# STM32WBA52 register map
File version: 0.1
CPU: CM33 r0p1, little endian, MPU, FPU, 4 interrupt priority bits
Registers are 32-bit, read-write, reset 0x0 unless marked. A register's access mark holds for its fields unless they carry their own. Offsets are from the block's base; [hi:lo] are bit positions; lines under a group give offsets from that group; {n}, {i} and the like mark numbered series; 'fields as' and 'values as' point back to an identical list.

## TSC — Touch sensing controller
Base 0x40024000
Same registers: SEC_TSC 0x50024000
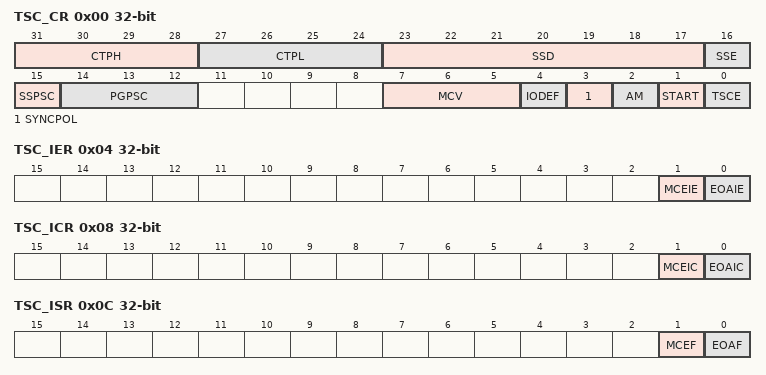
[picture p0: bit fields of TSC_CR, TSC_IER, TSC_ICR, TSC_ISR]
0x00 TSC_CR — TSC control register
  [31:28] CTPH — Charge transfer pulse high These bits are set and cleared by software. They define the duration of the high state of the charge transfer pulse (charge of C<sub>X</sub>). ... Note: These bits must not be modified when an acquisition is ongoing.
    0=1x t<sub>PGCLK</sub>; 1=2x t<sub>PGCLK</sub>; 15=16x t<sub>PGCLK</sub>
  [27:24] CTPL — Charge transfer pulse low These bits are set and cleared by software. They define the duration of the low state of the charge transfer pulse (transfer of charge from C<sub>X</sub> to C<sub>S</sub>). ... Note: These bits must not be modified when an acquisition is ongoing. Note: Some configurations are forbidden. Refer to the Section�21.3.4: Charge transfer acquisition sequence for details.
    values as CTPH
  [23:17] SSD — Spread spectrum deviation These bits are set and cleared by software. They define the spread spectrum deviation which consists in adding a variable number of periods of the SSCLK clock to the charge transfer pulse high state. ... Note: These bits must not be modified when an acquisition is ongoing.
    0=1x t<sub>SSCLK</sub>; 1=2x t<sub>SSCLK</sub>; 127=128x t<sub>SSCLK</sub>
  [16] SSE — Spread spectrum enable This bit is set and cleared by software to enable/disable the spread spectrum feature. Note: This bit must not be modified when an acquisition is ongoing.
    0=Spread spectrum disabled; 1=Spread spectrum enabled
  [15] SSPSC — Spread spectrum prescaler This bit is set and cleared by software. It selects the AHB clock divider used to generate the spread spectrum clock (SSCLK). Note: This bit must not be modified when an acquisition is ongoing.
    0=f<sub>HCLK</sub>; 1=f<sub>HCLK</sub> /2
  [14:12] PGPSC — Pulse generator prescaler These bits are set and cleared by software.They select the AHB clock divider used to generate the pulse generator clock (PGCLK). Note: These bits must not be modified when an acquisition is ongoing. Note: Some configurations are forbidden. Refer to the Section�21.3.4: Charge transfer acquisition sequence for details.
    0=f<sub>HCLK</sub>; 1=f<sub>HCLK</sub> /2; 2=f<sub>HCLK</sub> /4; 3=f<sub>HCLK</sub> /8; 4=f<sub>HCLK</sub> /16; 5=f<sub>HCLK</sub> /32; 6=f<sub>HCLK</sub> /64; 7=f<sub>HCLK</sub> /128
  [7:5] MCV — Max count value These bits are set and cleared by software. They define the maximum number of charge transfer pulses that can be generated before a max count error is generated. Note: These bits must not be modified when an acquisition is ongoing.
    0=255; 1=511; 2=1023; 3=2047; 4=4095; 5=8191; 6=16383
  [4] IODEF — I/O Default mode This bit is set and cleared by software. It defines the configuration of all the TSC I/Os when there is no ongoing acquisition. When there is an ongoing acquisition, it defines the configuration of all unused I/Os (not defined as sampling capacitor I/O or as channel I/O). Note: This bit must not be modified when an acquisition is ongoing.
    0=I/Os are forced to output push-pull low; 1=I/Os are in input floating
  [3] SYNCPOL — Synchronization pin polarity This bit is set and cleared by software to select the polarity of the synchronization input pin.
    0=Falling edge only; 1=Rising edge and high level
  [2] AM — Acquisition mode This bit is set and cleared by software to select the acquisition mode. Note: This bit must not be modified when an acquisition is ongoing.
    0=Normal acquisition mode (acquisition starts as soon as START bit is set); 1=Synchronized acquisition mode (acquisition starts if START bit is set and when the selected signal is detected on the SYNC input pin)
  [1] START — Start a new acquisition This bit is set by software to start a new acquisition. It is cleared by hardware as soon as the acquisition is complete or by software to cancel the ongoing acquisition.
    0=Acquisition not started; 1=Start a new acquisition
  [0] TSCE — Touch sensing controller enable This bit is set and cleared by software to enable/disable the touch sensing controller. Note: When the touch sensing controller is disabled, TSC registers settings have no effect.
    0=Touch sensing controller disabled; 1=Touch sensing controller enabled
0x04 TSC_IER — TSC interrupt enable register
  [1] MCEIE — Max count error interrupt enable This bit is set and cleared by software to enable/disable the max count error interrupt.
    0=Max count error interrupt disabled; 1=Max count error interrupt enabled
  [0] EOAIE — End of acquisition interrupt enable This bit is set and cleared by software to enable/disable the end of acquisition interrupt.
    0=End of acquisition interrupt disabled; 1=End of acquisition interrupt enabled
0x08 TSC_ICR — TSC interrupt clear register
  [1] MCEIC — Max count error interrupt clear This bit is set by software to clear the max count error flag and it is cleared by hardware when the flag is reset. Writing a ‘0’ has no effect.
    0=No effect; 1=Clears the corresponding MCEF of the TSC_ISR register
  [0] EOAIC — End of acquisition interrupt clear This bit is set by software to clear the end of acquisition flag and it is cleared by hardware when the flag is reset. Writing a ‘0’ has no effect.
    0=No effect; 1=Clears the corresponding EOAF of the TSC_ISR register
0x0C TSC_ISR ro — TSC interrupt status register
  [1] MCEF — Max count error flag This bit is set by hardware as soon as an analog I/O group counter reaches the max count value specified. It is cleared by software writing 1 to the bit MCEIC of the TSC_ICR register.
    0=No max count error (MCE) detected; 1=Max count error (MCE) detected
  [0] EOAF — End of acquisition flag This bit is set by hardware when the acquisition of all enabled group is complete (all GxS bits of all enabled analog I/O groups are set or when a max count error is detected). It is cleared by software writing 1 to the bit EOAIC of the TSC_ICR register.
    0=Acquisition is ongoing or not started; 1=Acquisition is complete
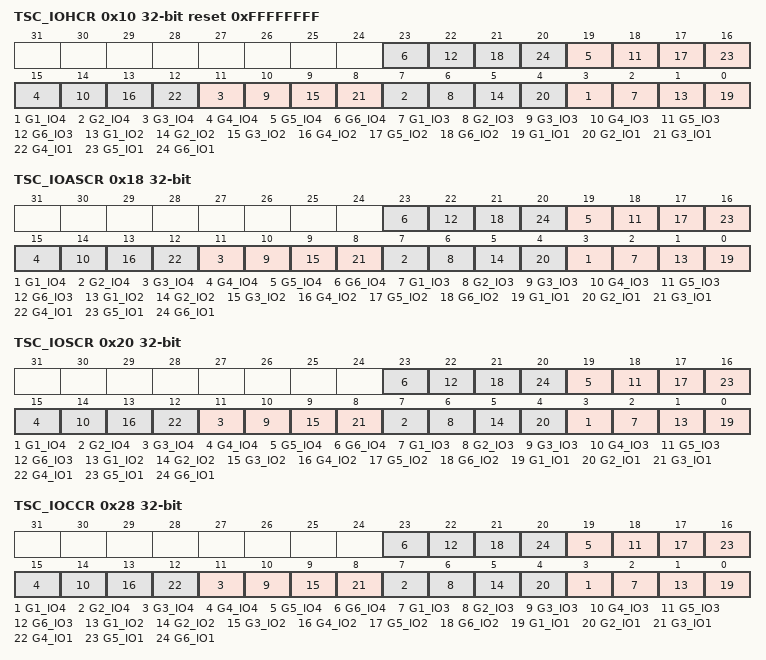
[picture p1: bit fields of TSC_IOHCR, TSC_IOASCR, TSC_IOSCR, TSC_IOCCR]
0x10 TSC_IOHCR reset 0xFFFFFFFF — TSC I/O hysteresis control register
  [all] fields
    0=Gx_IOy Schmitt trigger hysteresis disabled; 1=Gx_IOy Schmitt trigger hysteresis enabled
  [4n-1] G{n}_IO4 (n=1..6) — Gx_IOy Schmitt trigger hysteresis mode, x = 8 to 1, y = 4 to 1. These bits are set and cleared by software to enable/disable the Gx_IOy Schmitt trigger hysteresis. Note: These bits control the I/O Schmitt trigger hysteresis whatever the I/O control mode is (even if controlled by standard GPIO registers).
  [4n-2] G{n}_IO3 (n=1..6) — Gx_IOy Schmitt trigger hysteresis mode, x = 8 to 1, y = 4 to 1. These bits are set and cleared by software to enable/disable the Gx_IOy Schmitt trigger hysteresis. Note: These bits control the I/O Schmitt trigger hysteresis whatever the I/O control mode is (even if controlled by standard GPIO registers).
  [4n-3] G{n}_IO2 (n=1..6) — Gx_IOy Schmitt trigger hysteresis mode, x = 8 to 1, y = 4 to 1. These bits are set and cleared by software to enable/disable the Gx_IOy Schmitt trigger hysteresis. Note: These bits control the I/O Schmitt trigger hysteresis whatever the I/O control mode is (even if controlled by standard GPIO registers).
  [4n-4] G{n}_IO1 (n=1..6) — Gx_IOy Schmitt trigger hysteresis mode, x = 8 to 1, y = 4 to 1. These bits are set and cleared by software to enable/disable the Gx_IOy Schmitt trigger hysteresis. Note: These bits control the I/O Schmitt trigger hysteresis whatever the I/O control mode is (even if controlled by standard GPIO registers).
0x18 TSC_IOASCR — TSC I/O analog switch control register
  [all] fields
    0=Gx_IOy analog switch disabled (opened); 1=Gx_IOy analog switch enabled (closed)
  [4n-1] G{n}_IO4 (n=1..6) — Gx_IOy analog switch enable These bits are set and cleared by software to enable/disable the Gx_IOy analog switch. Note: These bits control the I/O analog switch whatever the I/O control mode is (even if controlled by standard GPIO registers).
  [4n-2] G{n}_IO3 (n=1..6) — Gx_IOy analog switch enable These bits are set and cleared by software to enable/disable the Gx_IOy analog switch. Note: These bits control the I/O analog switch whatever the I/O control mode is (even if controlled by standard GPIO registers).
  [4n-3] G{n}_IO2 (n=1..6) — Gx_IOy analog switch enable These bits are set and cleared by software to enable/disable the Gx_IOy analog switch. Note: These bits control the I/O analog switch whatever the I/O control mode is (even if controlled by standard GPIO registers).
  [4n-4] G{n}_IO1 (n=1..6) — Gx_IOy analog switch enable These bits are set and cleared by software to enable/disable the Gx_IOy analog switch. Note: These bits control the I/O analog switch whatever the I/O control mode is (even if controlled by standard GPIO registers).
0x20 TSC_IOSCR — TSC I/O sampling control register
  [all] fields
    0=Gx_IOy unused; 1=Gx_IOy used as sampling capacitor
  [4n-1] G{n}_IO4 (n=1..6) — Gx_IOy sampling mode These bits are set and cleared by software to configure the Gx_IOy as a sampling capacitor I/O. Only one I/O per analog I/O group must be defined as sampling capacitor. Note: These bits must not be modified when an acquisition is ongoing. Note: During the acquisition phase and even if the TSC peripheral alternate function is not enabled, as soon as the TSC_IOSCR bit is set, the corresponding GPIO analog switch is automatically controlled by the touch sensing controller.
  [4n-2] G{n}_IO3 (n=1..6) — Gx_IOy sampling mode These bits are set and cleared by software to configure the Gx_IOy as a sampling capacitor I/O. Only one I/O per analog I/O group must be defined as sampling capacitor. Note: These bits must not be modified when an acquisition is ongoing. Note: During the acquisition phase and even if the TSC peripheral alternate function is not enabled, as soon as the TSC_IOSCR bit is set, the corresponding GPIO analog switch is automatically controlled by the touch sensing controller.
  [4n-3] G{n}_IO2 (n=1..6) — Gx_IOy sampling mode These bits are set and cleared by software to configure the Gx_IOy as a sampling capacitor I/O. Only one I/O per analog I/O group must be defined as sampling capacitor. Note: These bits must not be modified when an acquisition is ongoing. Note: During the acquisition phase and even if the TSC peripheral alternate function is not enabled, as soon as the TSC_IOSCR bit is set, the corresponding GPIO analog switch is automatically controlled by the touch sensing controller.
  [4n-4] G{n}_IO1 (n=1..6) — Gx_IOy sampling mode These bits are set and cleared by software to configure the Gx_IOy as a sampling capacitor I/O. Only one I/O per analog I/O group must be defined as sampling capacitor. Note: These bits must not be modified when an acquisition is ongoing. Note: During the acquisition phase and even if the TSC peripheral alternate function is not enabled, as soon as the TSC_IOSCR bit is set, the corresponding GPIO analog switch is automatically controlled by the touch sensing controller.
0x28 TSC_IOCCR — TSC I/O channel control register
  [all] fields
    0=Gx_IOy unused; 1=Gx_IOy used as channel
  [4n-1] G{n}_IO4 (n=1..6) — Gx_IOy channel mode These bits are set and cleared by software to configure the Gx_IOy as a channel I/O. Note: These bits must not be modified when an acquisition is ongoing. Note: During the acquisition phase and even if the TSC peripheral alternate function is not enabled, as soon as the TSC_IOCCR bit is set, the corresponding GPIO analog switch is automatically controlled by the touch sensing controller.
  [4n-2] G{n}_IO3 (n=1..6) — Gx_IOy channel mode These bits are set and cleared by software to configure the Gx_IOy as a channel I/O. Note: These bits must not be modified when an acquisition is ongoing. Note: During the acquisition phase and even if the TSC peripheral alternate function is not enabled, as soon as the TSC_IOCCR bit is set, the corresponding GPIO analog switch is automatically controlled by the touch sensing controller.
  [4n-3] G{n}_IO2 (n=1..6) — Gx_IOy channel mode These bits are set and cleared by software to configure the Gx_IOy as a channel I/O. Note: These bits must not be modified when an acquisition is ongoing. Note: During the acquisition phase and even if the TSC peripheral alternate function is not enabled, as soon as the TSC_IOCCR bit is set, the corresponding GPIO analog switch is automatically controlled by the touch sensing controller.
  [4n-4] G{n}_IO1 (n=1..6) — Gx_IOy channel mode These bits are set and cleared by software to configure the Gx_IOy as a channel I/O. Note: These bits must not be modified when an acquisition is ongoing. Note: During the acquisition phase and even if the TSC peripheral alternate function is not enabled, as soon as the TSC_IOCCR bit is set, the corresponding GPIO analog switch is automatically controlled by the touch sensing controller.
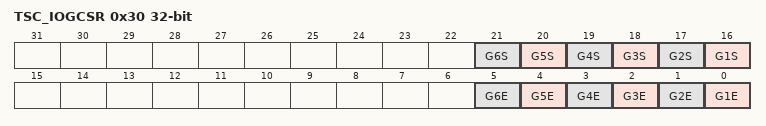
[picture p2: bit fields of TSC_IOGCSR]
0x30 TSC_IOGCSR access per field — TSC I/O group control status register
  [n+15] G{n}S ro (n=1..6) — Analog I/O group x status These bits are set by hardware when the acquisition on the corresponding enabled analog I/O group x is complete. They are cleared by hardware when a new acquisition is started. Note: When a max count error is detected the remaining GxS bits of the enabled analog I/O groups are not set.
    0=Acquisition on analog I/O group x is ongoing or not started; 1=Acquisition on analog I/O group x is complete
  [n-1] G{n}E rw (n=1..6) — Analog I/O group x enable These bits are set and cleared by software to enable/disable the acquisition (counter is counting) on the corresponding analog I/O group x.
    0=Acquisition on analog I/O group x disabled; 1=Acquisition on analog I/O group x enabled
{0x30+4i} TSC_IOG{i}CR ro (i=1..6) — TSC I/O group {i} counter register
  [13:0] CNT — Counter value These bits represent the number of charge transfer cycles generated on the analog I/O group x to complete its acquisition (voltage across C<sub>S</sub> has reached the threshold).
